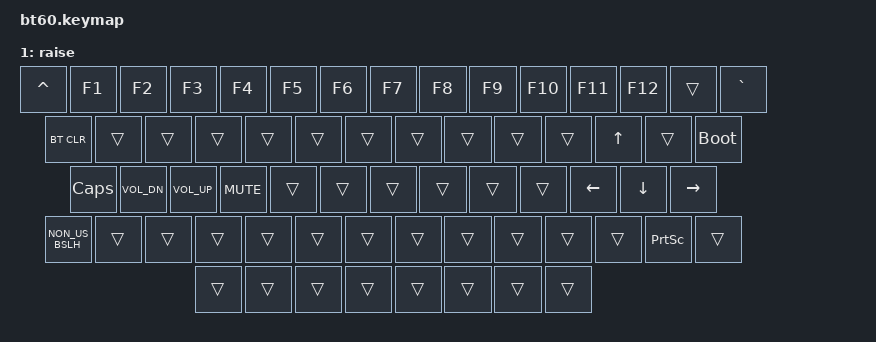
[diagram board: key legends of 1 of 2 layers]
#include <behaviors.dtsi>
#include <dt-bindings/zmk/keys.h>
#include <dt-bindings/zmk/bt.h>
#include <dt-bindings/zmk/rgb.h>
#include <dt-bindings/zmk/backlight.h>

/ {
	keymap {
		compatible = "zmk,keymap";

		default_layer {
				// ------------------------------------------------------------------------------------------
				// |  ESC  |  1  |  2  |  3  |  4  |  5  |  6  |  7  |  8  |  9  |  0  |  -  |  =  |   \  | DEL
				// | TAB  |  Q  |  W  |  E  |  R  |  T  |  Y  |  U  |  I  |  O  |  P  |  [  |  ]  |  BSPC |
				// | CTRL  |  A  |  S  |  D  |  F  |  G  |  H  |  J  |  K  |  L  |  ;  |  '  |     ENTER
				// | SHIFT | NON-US \ |  Z  |  X  |  C  |  V  |  B  |  N  |  M  |  ,  |  .  | / | SHIFT | FN-LAYER
				// |  CTL  |  WIN  |  ALT  |            SPACE               | ALT | 1    |  MENU    |  CTRL
				// ------------------------------------------------------------------------------------------
			bindings = <

				&kp ESC &kp N1 &kp N2 &kp N3 &kp N4 &kp N5 &kp N6 &kp N7 &kp  N8   &kp  N9 &kp  N0  &kp MINUS &kp EQUAL &kp BSLH &kp DEL
				&kp TAB  &kp Q  &kp W  &kp E  &kp R  &kp T  &kp Y  &kp U  &kp  I    &kp  O  &kp  P   &kp LBKT &kp RBKT   &kp BSPC
				&kp LCTRL  &kp A  &kp S  &kp D  &kp F  &kp G  &kp H  &kp J  &kp  K    &kp  L  &kp SEMI &kp SQT            &kp RET
				&kp LSHFT &kp NON_US_BSLH &kp Z  &kp X  &kp C  &kp V  &kp B  &kp N  &kp M  &kp COMMA &kp DOT &kp FSLH &kp RSHFT &mo 1
				&kp LCTRL &kp LGUI &kp LALT            &kp SPACE                          &kp RALT  &kp RGUI    &kp RCTRL
			>;
			sensor-bindings = <&inc_dec_kp C_VOL_UP C_VOL_DN>;
		};
		raise {
			bindings = <
				&kp CARET &kp F1 &kp F2 &kp F3 &kp F4 &kp F5 &kp F6 &kp F7 &kp F8 &kp F9 &kp F10 &kp F11 &kp F12 &trans &kp GRAVE
				&bt BT_CLR &trans &trans &trans &trans &trans &trans &trans &trans &trans &trans &kp UP_ARROW &trans &bootloader
				&kp CAPS &kp C_VOL_DN &kp C_VOL_UP &kp C_MUTE &trans &trans &trans &trans &trans &trans &kp LEFT_ARROW &kp DOWN_ARROW &kp RIGHT_ARROW 
				&kp NON_US_BSLH &trans &trans &trans &trans &trans &trans &trans &trans &trans &trans &trans &kp PSCRN &trans
				&trans &trans  &trans              &trans                            &trans   &trans   &trans &trans
			>;
			sensor-bindings = <&inc_dec_kp C_VOL_UP C_VOL_DN>;
		};
	};
};
